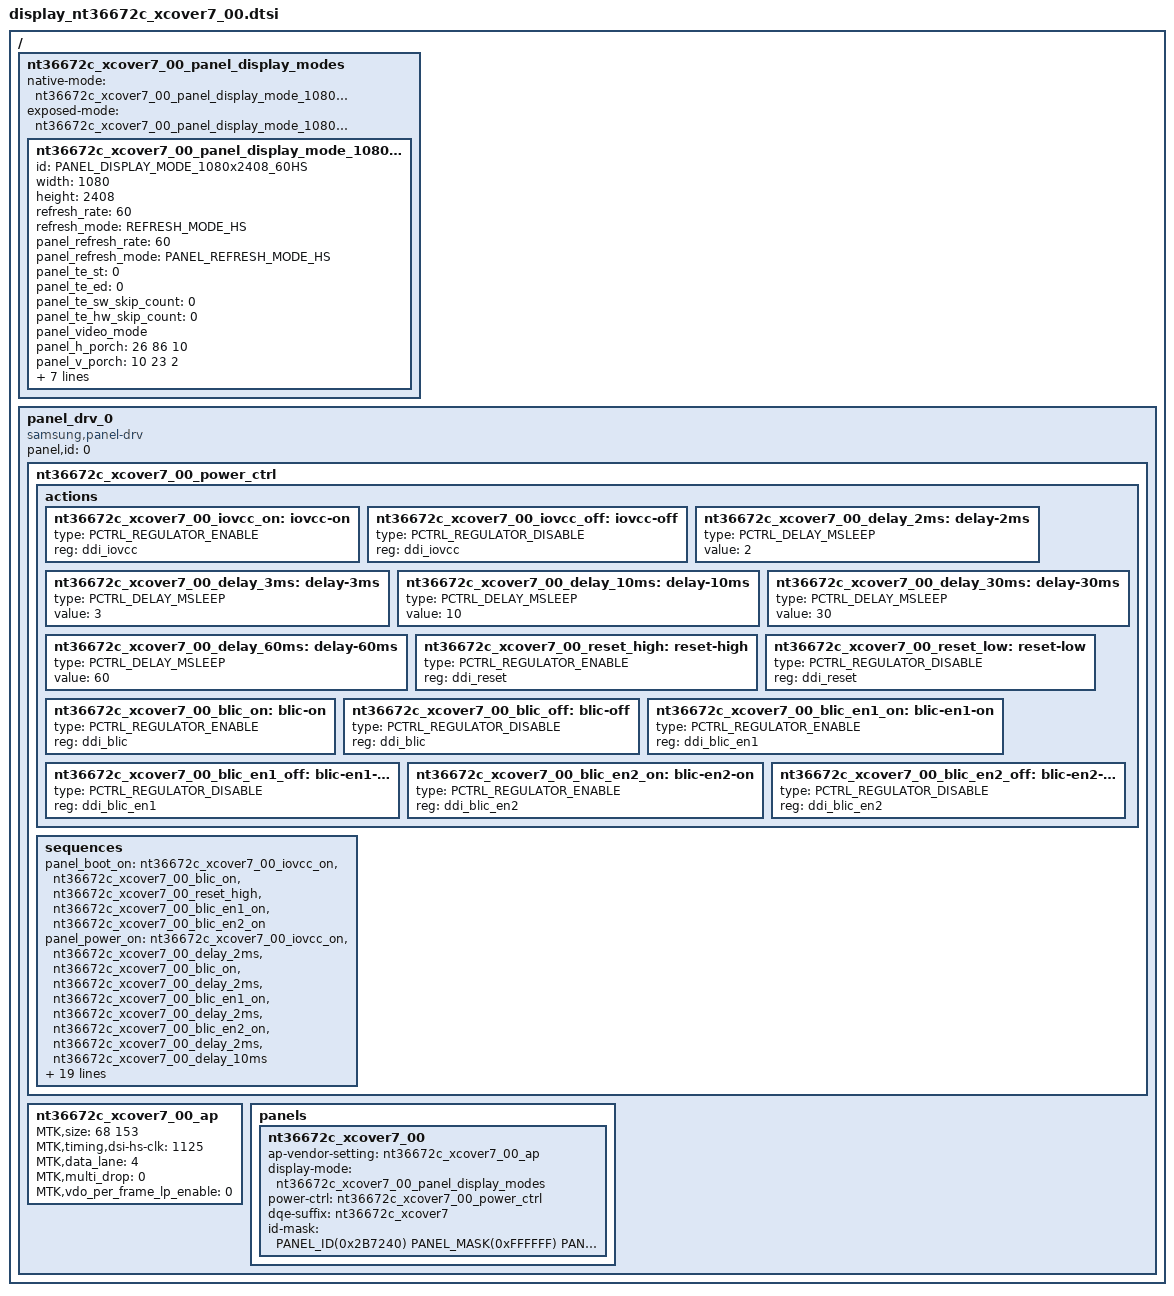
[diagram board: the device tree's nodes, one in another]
/*
 * Samsung Exynos SoC series Panel driver
 *
 * Copyright (c) 2020 Samsung Electronics Co., Ltd
 *
 * This program is free software; you can redistribute it and/or modify
 * it under the terms of the GNU General Public License version 2 as
 * published by the Free Software Foundation.
 */

#include <dt-bindings/display/panel-display.h>

/ {
	fragment@panel_display_mode {
		target-path = "/";
		__overlay__ {
			nt36672c_xcover7_00_panel_display_modes:
			nt36672c_xcover7_00_panel_display_modes {
				native-mode = <&nt36672c_xcover7_00_panel_display_mode_1080x2408_60hs>;
				exposed-mode = <
					&nt36672c_xcover7_00_panel_display_mode_1080x2408_60hs
				>;

				nt36672c_xcover7_00_panel_display_mode_1080x2408_60hs:
				nt36672c_xcover7_00_panel_display_mode_1080x2408_60hs {
					id = PANEL_DISPLAY_MODE_1080x2408_60HS;
					width = <1080>;
					height = <2408>;
					/* timing parameters */
					refresh_rate = <60>;			/* logical refresh rate */
					refresh_mode = <REFRESH_MODE_HS>;
					panel_refresh_rate = <60>;		/* panel internal refresh rate */
					panel_refresh_mode = <PANEL_REFRESH_MODE_HS>;
					panel_te_st = <0>;				/* te rising */
					panel_te_ed = <0>;				/* te falling */
					panel_te_sw_skip_count = <0>;	/* s/w te modulation */
					panel_te_hw_skip_count = <0>;	/* h/w te modulation */

					/* video mode parameters */
					panel_video_mode;
					panel_h_porch = <26 86 10>;
					panel_v_porch = <10 23 2>;
					/* dsc parameters */
					dsc_en = <0>;			/* 0:Disable, 1:Enable */
					dsc_cnt = <1>;			/* used DSC count */
					dsc_slice_num = <2>;	/* count of dsc slice */
					dsc_slice_w = <540>;	/* width of dsc slice */
					dsc_slice_h = <40>;	/* height of dsc slice */

					/* dsi parameters */
					cmd_lp_ref = <7741>;

					/*qos parameters */
					disp_qos_fps = <60>;
				};
			};
		};
	};
};

/ {
	fragment@panel_drv {
		target-path = "/";
		__overlay__ {
			panel_drv_0: panel_drv_0 {
				status = "okay";
				compatible = "samsung,panel-drv";
				panel,id = <0>;

				nt36672c_xcover7_00_power_ctrl:
				nt36672c_xcover7_00_power_ctrl {
					actions {
						nt36672c_xcover7_00_iovcc_on: iovcc-on {
							type = <PCTRL_REGULATOR_ENABLE>;
							reg = <&ddi_iovcc>;
						};
						nt36672c_xcover7_00_iovcc_off: iovcc-off {
							type = <PCTRL_REGULATOR_DISABLE>;
							reg = <&ddi_iovcc>;
						};
						nt36672c_xcover7_00_delay_2ms: delay-2ms {
							type = <PCTRL_DELAY_MSLEEP>;
							value = <2>;
						};
						nt36672c_xcover7_00_delay_3ms: delay-3ms {
							type = <PCTRL_DELAY_MSLEEP>;
							value = <3>;
						};
						nt36672c_xcover7_00_delay_10ms: delay-10ms {
							type = <PCTRL_DELAY_MSLEEP>;
							value = <10>;
						};
						nt36672c_xcover7_00_delay_30ms: delay-30ms {
							type = <PCTRL_DELAY_MSLEEP>;
							value = <30>;
						};
						nt36672c_xcover7_00_delay_60ms: delay-60ms {
							type = <PCTRL_DELAY_MSLEEP>;
							value = <60>;
						};
						nt36672c_xcover7_00_reset_high: reset-high {
							type = <PCTRL_REGULATOR_ENABLE>;
							reg = <&ddi_reset>;
						};
						nt36672c_xcover7_00_reset_low: reset-low {
							type = <PCTRL_REGULATOR_DISABLE>;
							reg = <&ddi_reset>;
						};
						nt36672c_xcover7_00_blic_on: blic-on {
							type = <PCTRL_REGULATOR_ENABLE>;
							reg = <&ddi_blic>;
						};
						nt36672c_xcover7_00_blic_off: blic-off {
							type = <PCTRL_REGULATOR_DISABLE>;
							reg = <&ddi_blic>;
						};
						nt36672c_xcover7_00_blic_en1_on: blic-en1-on {
							type = <PCTRL_REGULATOR_ENABLE>;
							reg = <&ddi_blic_en1>;
						};
						nt36672c_xcover7_00_blic_en1_off: blic-en1-off {
							type = <PCTRL_REGULATOR_DISABLE>;
							reg = <&ddi_blic_en1>;
						};
						nt36672c_xcover7_00_blic_en2_on: blic-en2-on {
							type = <PCTRL_REGULATOR_ENABLE>;
							reg = <&ddi_blic_en2>;
						};
						nt36672c_xcover7_00_blic_en2_off: blic-en2-off {
							type = <PCTRL_REGULATOR_DISABLE>;
							reg = <&ddi_blic_en2>;
						};
					};
					sequences {
						panel_boot_on = <
							&nt36672c_xcover7_00_iovcc_on
							&nt36672c_xcover7_00_blic_on
							&nt36672c_xcover7_00_reset_high
							&nt36672c_xcover7_00_blic_en1_on
							&nt36672c_xcover7_00_blic_en2_on
						>;

						panel_power_on = <
							&nt36672c_xcover7_00_iovcc_on
							&nt36672c_xcover7_00_delay_2ms
							&nt36672c_xcover7_00_blic_on
							&nt36672c_xcover7_00_delay_2ms
							&nt36672c_xcover7_00_blic_en1_on
							&nt36672c_xcover7_00_delay_2ms
							&nt36672c_xcover7_00_blic_en2_on
							&nt36672c_xcover7_00_delay_2ms
							&nt36672c_xcover7_00_delay_10ms
						>;

						panel_reset_lp11 = <
							&nt36672c_xcover7_00_reset_high
							&nt36672c_xcover7_00_delay_3ms
							&nt36672c_xcover7_00_reset_low
							&nt36672c_xcover7_00_delay_3ms
							&nt36672c_xcover7_00_reset_high
							&nt36672c_xcover7_00_delay_10ms
						>;

						panel_power_off = <
							&nt36672c_xcover7_00_delay_60ms
							&nt36672c_xcover7_00_reset_low
							&nt36672c_xcover7_00_delay_2ms
							&nt36672c_xcover7_00_blic_en2_off
							&nt36672c_xcover7_00_delay_2ms
							&nt36672c_xcover7_00_blic_en1_off
							&nt36672c_xcover7_00_delay_2ms
							&nt36672c_xcover7_00_blic_off
							&nt36672c_xcover7_00_delay_2ms
							&nt36672c_xcover7_00_iovcc_off
							&nt36672c_xcover7_00_delay_30ms
						>;
					};
				};

				nt36672c_xcover7_00_ap:nt36672c_xcover7_00_ap {
					MTK,size = <68 153>; /* 68.43mm(H) x 152.57mm(V)  */
					MTK,timing,dsi-hs-clk = <1125>;
					MTK,data_lane = <4>;		/* number of using data lane */
					MTK,multi_drop = <0>;
					MTK,vdo_per_frame_lp_enable = <0>;
				};

				panels {
					nt36672c_xcover7_00: nt36672c_xcover7_00 {
						ap-vendor-setting = <&nt36672c_xcover7_00_ap>;
						display-mode = <&nt36672c_xcover7_00_panel_display_modes>;
						power-ctrl = <&nt36672c_xcover7_00_power_ctrl>;
						dqe-suffix = "nt36672c_xcover7";
						id-mask = <
							PANEL_ID(0x2B7240) PANEL_MASK(0xFFFFFF)
							PANEL_ID(0x000000) PANEL_MASK(0x000000)
						>;
					};
				};
			};
		};
	};
};

